# R9A02G021 register map
Vendor: Renesas Electronics Corporation; Series: RISC-V; File version: 1.10.00 + 202304131714_CPU
CPU: other r0p0, little endian, no MPU, no FPU, VTOR, 4 interrupt priority bits, 32 interrupts
Registers are 8-bit, read-write, reset 0x0 unless marked. A register's access mark holds for its fields unless they carry their own. Offsets are from the block's base; [hi:lo] are bit positions; {n}, {i} and the like mark numbered series; 'fields as' and 'values as' point back to an identical list.

## REMC — Remote Control Signal Receiver
Base 0x40092100
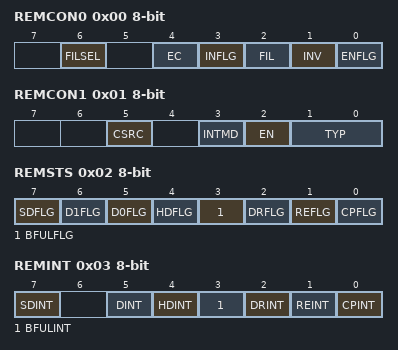
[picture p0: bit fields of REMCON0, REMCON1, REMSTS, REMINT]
0x00 REMCON0 — Function Select Register 0
  [6] FILSEL — Digital Filter Function Select
    0=Digital filter for matching three times; 1=Digital filter for matching two times
  [4] EC — Receive Error Capture Operation Select
    0=Captures the data after an error pattern is received; 1=Does not capture the data after an error pattern is received
  [3] INFLG ro — Input Signal Flag
    0=The level of the internal input signal of the remote control signal receiver is low; 1=The level of the internal input signal of the remote control signal receiver is high
  [2] FIL — Digital Filter Enable or Disable Setting
    0=Disables the digital filter for matching three or two times; 1=Enables the digital filter for matching three or two times
  [1] INV — Input Signal Inversion
    0=Not inverted; 1=Inverted
  [0] ENFLG ro — Remote Control Status Flag
    0=Stopped; 1=Operating
0x01 REMCON1 — Function Select Register 1
  [5] CSRC — Operating Clock Select
    0=REMCLCLK/REMCSCLK; 1=Timer interrupt (TAU0_ENDI6) Use channel 6 of timer array unit in the interval timer mode
  [3] INTMD — Interrupt Mode Select
    0=Normal interrupt mode (OR condition); 1=Sequential interrupt mode (AND condition)
  [2] EN — Remote Control
    0=Operation disabled; 1=Operation enabled
  [1:0] TYP — Receive Mode Select
    0=Format A; 1=Format B; 2=Format C; 3=Setting prohibited
0x02 REMSTS — Status Register
  [7] SDFLG ro — Special Data Pattern Match Flag
    0=Mismatch; 1=Match
  [6] D1FLG ro — Data 1 Pattern Match Flag
    0=Mismatch; 1=Match
  [5] D0FLG ro — Data 0 Pattern Match Flag
    0=Mismatch; 1=Match
  [4] HDFLG ro — Header Pattern Match Flag
    0=Mismatch; 1=Match
  [3] BFULFLG — Receive Buffer Full Flag
    0=Receive buffer is empty; 1=Receive buffer is full (64 bits received)
  [2] DRFLG ro — Data Receiving Flag
    0=Waiting for data reception; 1=Data is being received
  [1] REFLG ro — Receive Error Flag
    0=No error has occurred; 1=An error has occurred
  [0] CPFLG ro — Compare Match Flag
    0=Mismatch; 1=Match
0x03 REMINT — Interrupt Control Register
  [all] fields
    0=Disabled; 1=Enabled
  [7] SDINT — Special Data Pattern Match Interrupt Enable
  [5] DINT — Data 0 Pattern or Data 1 Pattern Match Interrupt Enable
  [4] HDINT — Header Pattern Match Interrupt Enable
  [3] BFULINT — Receive Buffer Full Interrupt Enable
  [2] DRINT — Data Receiving Interrupt Enable
  [1] REINT — Receive Error Interrupt Enable
  [0] CPINT — Compare Match Interrupt Enable
0x05 REMCPC — Compare Control Register
  [3:0] CPN — Compare Bit Count Specification
0x06 REMCPD 16-bit — Compare Value Setting Register
0x08 HDPMIN 16-bit — Header Pattern Minimum Width Setting Register
  [10:0] HDMIN — Set the minimum width of the header pattern
0x0A HDPMAX 16-bit — Header Pattern Maximum Width Setting Register
  [10:0] HDMAX — Set the maximum width of the header pattern
0x0C D0PMIN — Data 0 Pattern Minimum Width Setting Register
0x0D D0PMAX — Data 0 Pattern Maximum Width Setting Register
0x0E D1PMIN — Data 1 Pattern Minimum Width Setting Register
0x0F D1PMAX — Data 1 Pattern Maximum Width Setting Register
0x10 SDPMIN 16-bit — Special Data Pattern Minimum Width Setting Register
  [10:0] SDMIN — Set the minimum width of the special data pattern
0x12 SDPMAX 16-bit — Special Data Pattern Maximum Width Setting Register
  [10:0] SDMAX — Set the maximum width of the special data pattern
0x14 REMPE 16-bit — Pattern End Setting Register
  [10:0] PE — Set the width of the pattern end
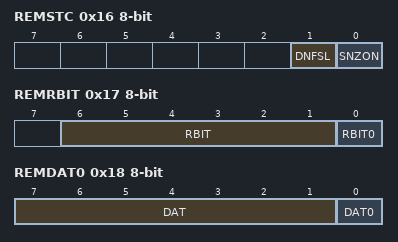
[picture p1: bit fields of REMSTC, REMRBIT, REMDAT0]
0x16 REMSTC — Receiver Standby Control Register
  [1] DNFSL — Digital Filter Clock Selection
    0=REMC operating clock is selected as a sampling clock; 1=REMCLCLK/REMCSCLK is selected as a sampling clock
  [0] SNZON — Snooze Mode Operation Control
    0=Disables transition from Software Standby mode to Snooze mode; 1=Enables transition from Software Standby mode to Snooze mode
0x17 REMRBIT — Receive Bit Count Register
  [6:1] RBIT ro — Receive Bit Count Check (bit 6 to 1)
  [0] RBIT0 — Receive Bit Count Check (bit 0)
    0=This register is cleared (0x00); other=Others (Setting prohibited)
0x18 REMDAT0 — Receive Data 0 Register
  [7:1] DAT ro — Receive Data 0 Store (bit 7 to 1)
  [0] DAT0 — Receive Data 0 Store (bit 0)
    values as REMRBIT.RBIT0
{0x18+i} REMDAT{i} (i=1..7) ro — Receive Data {i} Register
  [7:0] DAT — Receive Data Store
0x20 REMTIM 16-bit ro — Measurement Result Register
  [10:0] TIM — Measurement Result
